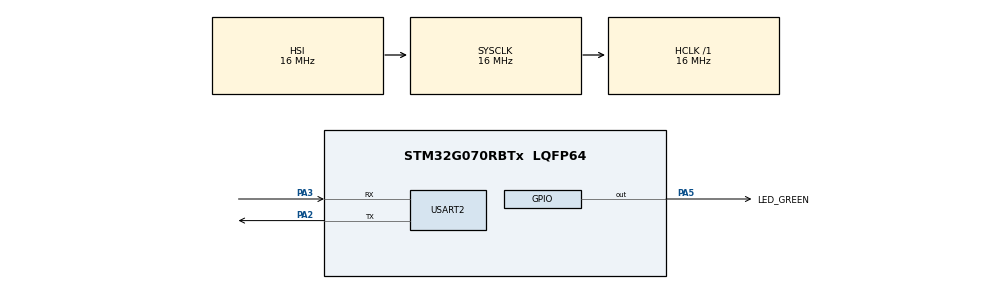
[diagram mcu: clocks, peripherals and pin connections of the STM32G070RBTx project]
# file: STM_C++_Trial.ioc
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Mcu.Family=STM32G0
Mcu.Name=STM32G070RBTx
Mcu.Package=LQFP64
PA13.GPIO_Label=TMS
PA13.Mode=Serial_Wire
PA13.Signal=SYS_SWDIO
PA14-BOOT0.GPIO_Label=TCK
PA14-BOOT0.Mode=Serial_Wire
PA14-BOOT0.Signal=SYS_SWCLK
PA2.GPIO_PuPd=GPIO_PULLUP
PA2.Mode=Asynchronous
PA2.Signal=USART2_TX
PA3.GPIO_PuPd=GPIO_PULLUP
PA3.Mode=Asynchronous
PA3.Signal=USART2_RX
PA5.GPIO_Label=LED_GREEN
PA5.GPIO_Speed=GPIO_SPEED_FREQ_HIGH
PA5.Signal=GPIO_Output
PC13.Mode=SYS_WakeUp1
PC13.Signal=SYS_WKUP2
PC14-OSC32_IN\ (PC14).Mode=LSE-External-Oscillator
PC14-OSC32_IN\ (PC14).Signal=RCC_OSC32_IN
PC15-OSC32_OUT\ (PC15).Mode=LSE-External-Oscillator
PC15-OSC32_OUT\ (PC15).Signal=RCC_OSC32_OUT
PF0-OSC_IN\ (PF0).GPIO_Label=MCO
PF0-OSC_IN\ (PF0).Mode=HSE-External-Clock-Source
PF0-OSC_IN\ (PF0).Signal=RCC_OSC_IN
ProjectManager.HeapSize=0x200
ProjectManager.StackSize=0x400
ProjectManager.TargetToolchain=STM32CubeIDE
RCC.AHBFreq_Value=16000000
RCC.CortexFreq_Value=16000000
RCC.EXTERNAL_CLOCK_VALUE=12288000
RCC.HCLKFreq_Value=16000000
RCC.HSE_VALUE=8000000
RCC.HSI_VALUE=16000000
RCC.SYSCLKFreq_VALUE=16000000
RCC.VCOOutputFreq_Value=128000000
USART2.VirtualMode-Asynchronous=VM_ASYNC
USART2.WordLength=WORDLENGTH_7B
VP_SYS_VS_DBSignals.Mode=DisableDeadBatterySignals
board=NUCLEO-G070RB

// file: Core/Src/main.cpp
/* USER CODE BEGIN Header */
/**
  ******************************************************************************
  * @file           : main.c
  * @brief          : Main program body
  ******************************************************************************
  * @attention
  *
  * <h2><center>&copy; Copyright (c) 2022 STMicroelectronics.
  * All rights reserved.</center></h2>
  *
  * This software component is licensed by ST under BSD 3-Clause license,
  * the "License"; You may not use this file except in compliance with the
  * License. You may obtain a copy of the License at:
  *                        opensource.org/licenses/BSD-3-Clause
  *
  ******************************************************************************
  */
/* USER CODE END Header */
#include "main.h"
#include "usart.h"
#include "gpio.h"

/* USER CODE BEGIN Includes */
#include "led.h"
/* USER CODE END Includes */

/* USER CODE BEGIN PV */
led_main led;		// Initialize class
/* USER CODE END PV */

void SystemClock_Config(void);

int main(void)
{

  /* MCU Configuration--------------------------------------------------------*/

  /* Reset of all peripherals, Initializes the Flash interface and the Systick. */
  HAL_Init();

  /* Configure the system clock */
  SystemClock_Config();

  /* Initialize all configured peripherals */
  MX_GPIO_Init();
  MX_USART2_UART_Init();
  /* USER CODE BEGIN 2 */
//  led_main();
  /* USER CODE END 2 */

  /* Infinite loop */
  while (1)
  {

    /* USER CODE BEGIN 3 */
	  led.on();
	  led.off();
  }
  /* USER CODE END 3 */
}

void SystemClock_Config(void)
{
  RCC_OscInitTypeDef RCC_OscInitStruct = {0};
  RCC_ClkInitTypeDef RCC_ClkInitStruct = {0};
  RCC_PeriphCLKInitTypeDef PeriphClkInit = {0};

  /** Configure the main internal regulator output voltage
  */
  HAL_PWREx_ControlVoltageScaling(PWR_REGULATOR_VOLTAGE_SCALE1);
  /** Initializes the RCC Oscillators according to the specified parameters
  * in the RCC_OscInitTypeDef structure.
  */
  RCC_OscInitStruct.OscillatorType = RCC_OSCILLATORTYPE_HSI;
  RCC_OscInitStruct.HSIState = RCC_HSI_ON;
  RCC_OscInitStruct.HSIDiv = RCC_HSI_DIV1;
  RCC_OscInitStruct.HSICalibrationValue = RCC_HSICALIBRATION_DEFAULT;
  RCC_OscInitStruct.PLL.PLLState = RCC_PLL_NONE;
  if (HAL_RCC_OscConfig(&RCC_OscInitStruct) != HAL_OK)
  {
    Error_Handler();
  }
  /** Initializes the CPU, AHB and APB buses clocks
  */
  RCC_ClkInitStruct.ClockType = RCC_CLOCKTYPE_HCLK|RCC_CLOCKTYPE_SYSCLK
                              |RCC_CLOCKTYPE_PCLK1;
  RCC_ClkInitStruct.SYSCLKSource = RCC_SYSCLKSOURCE_HSI;
  RCC_ClkInitStruct.AHBCLKDivider = RCC_SYSCLK_DIV1;
  RCC_ClkInitStruct.APB1CLKDivider = RCC_HCLK_DIV1;

  if (HAL_RCC_ClockConfig(&RCC_ClkInitStruct, FLASH_LATENCY_0) != HAL_OK)
  {
    Error_Handler();
  }
  /** Initializes the peripherals clocks
  */
  PeriphClkInit.PeriphClockSelection = RCC_PERIPHCLK_USART2;
  PeriphClkInit.Usart2ClockSelection = RCC_USART2CLKSOURCE_PCLK1;
  if (HAL_RCCEx_PeriphCLKConfig(&PeriphClkInit) != HAL_OK)
  {
    Error_Handler();
  }
}

void Error_Handler(void)
{
  __disable_irq();
  while (1)
  {
  }
}

/************************ (C) COPYRIGHT STMicroelectronics *****END OF FILE****/
